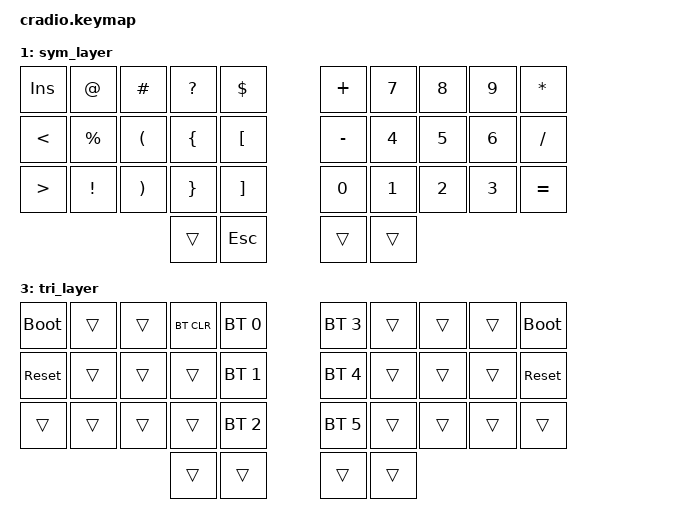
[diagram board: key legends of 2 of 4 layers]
// Copyright (c) 2022 The ZMK Contributors
// SPDX-License-Identifier: MIT

#include <behaviors.dtsi>
#include <dt-bindings/zmk/keys.h>
#include <dt-bindings/zmk/bt.h>

// Home row mods macro
#define HRML(k1,k2,k3,k4) &ht LCTRL k1  &ht LGUI k2  &ht LALT k3  &ht LCTRL k4
#define HRMR(k1,k2,k3,k4) &ht RCTRL k1  &ht RALT k2  &ht RGUI k3  &ht RCTRL k4

#define BASE    0
#define SYM     1
#define NAV     2

/ {
    behaviors {
        ht: hold_tap {
            compatible = "zmk,behavior-hold-tap";
            #binding-cells = <2>;
            flavor = "tap-preferred";
            tapping-term-ms = <220>;
            quick-tap-ms = <150>;
            require-prior-idle-ms = <100>;
            bindings = <&kp>, <&kp>;
        };
    };

    conditional_layers {
        compatible = "zmk,conditional-layers";
        tri_layer {
            if-layers = <1 2>;
            then-layer = <3>;
        };
    };

    keymap {
        compatible = "zmk,keymap";
        default_layer {
            bindings = <
        //╭──────────┬──────────┬──────────┬──────────┬──────────╮   ╭──────────┬──────────┬──────────┬──────────┬──────────╮
        //│  Q       │  W       │  E       │  R       │  T       │   │  Y       │  U       │  I       │  O       │  P       │
            &kp Q      &kp W      &kp E      &kp R      &kp T          &kp Y      &kp U      &kp I      &kp O      &kp P
        //├──────────┼──────────┼──────────┼──────────┼──────────┤   ├──────────┼──────────┼──────────┼──────────┼──────────┤
        //│  A       │  S       │  D       │  F       │  G       │   │  H       │  J       │  K       │  L       │          │
            HRML(A,     S,         D,         F)        &kp G          &kp H      HRMR(J,     K,         L,        BSPC)
        //├──────────┼──────────┼──────────┼──────────┼──────────┤   ├──────────┼──────────┼──────────┼──────────┼──────────┤
        //│  Z       │  X       │  C       │  V       │  B       │   │  N       │  M       │ , <      │ . >      │          │
            &kp Z      &kp X      &kp C      &kp V      &kp B          &kp N      &kp M      &kp COMMA  &kp DOT    &kp ENTER
        //╰──────────┴──────────┴──────────┼──────────┼──────────┤   ├──────────┼──────────┼──────────┴──────────┴──────────╯
                                           &lt NAV TAB &kp LSHFT     &kp BSPC   &lt SYM SPACE
        //                                 ╰──────────┴──────────╯   ╰──────────┴──────────╯
            >;
        };

        sym_layer {
            bindings = <
        //╭──────────┬──────────┬──────────┬──────────┬──────────╮   ╭──────────┬──────────┬──────────┬──────────┬──────────╮
        //│  !       │  @       │  #       │  ?       │  $       │   │  +       │  7       │  8       │  9       │  *       │
            &kp INS    &kp AT     &kp HASH   &kp QMARK  &kp DLLR       &kp PLUS   &kp N7     &kp N8     &kp N9     &kp ASTRK 
        //├──────────┼──────────┼──────────┼──────────┼──────────┤   ├──────────┼──────────┼──────────┼──────────┼──────────┤
        //│  <       │  %       │  (       │  {       │  [       │   │  -       │  4       │  5       │  6       │  /       │
            &kp LT    &kp PRCNT   &kp LPAR   &kp LBRC   &kp LBKT       &kp MINUS  &kp N4     &kp N5     &kp N6     &kp FSLH  
        //├──────────┼──────────┼──────────┼──────────┼──────────┤   ├──────────┼──────────┼──────────┼──────────┼──────────┤
        //│  >       │  !       │  )       │  }       │  ]       │   │  0       │  1       │  2       │  3       │  =       │
            &kp GT     &kp EXCL   &kp RPAR   &kp RBRC   &kp RBKT       &kp N0     &kp N1     &kp N2     &kp N3     &kp EQUAL 
        //╰──────────┴──────────┴──────────┼──────────┼──────────┤   ├──────────┼──────────┼──────────┴──────────┴──────────╯
                                             &trans     &kp ESC        &trans     &trans
        //                                 ╰──────────┴──────────╯   ╰──────────┴──────────╯
            >;
        };

        nav_layer {
            bindings = <
        //╭──────────┬──────────┬──────────┬──────────┬──────────╮   ╭──────────┬──────────┬──────────┬──────────┬──────────╮
        //│          │          │  ;       │  ^       │          │   │  PAGE UP │  HOME    │  UP      │  END     │  DELETE  │
            &trans     &trans     &kp SEMI   &kp CARET  &trans         &kp PG_UP  &kp HOME   &kp UARW   &kp END    &kp DEL   
        //├──────────┼──────────┼──────────┼──────────┼──────────┤   ├──────────┼──────────┼──────────┼──────────┼──────────┤
        //│  `       │  ~       │  _       │  &       │  │       │   │  PAGE DN │  LEFT    │  DOWN    │  RIGHT   │  BSPC    │
           HRML(GRAVE, TILDE,     UNDER,     AMPS)      &kp PIPE       &kp PG_DN  &kp LARW   &kp DARW   &kp RARW   &trans
        //├──────────┼──────────┼──────────┼──────────┼──────────┤   ├──────────┼──────────┼──────────┼──────────┼──────────┤
        //│ INSERT   │ CAPS     │  :       │  \       │          │   │  &       │  _       │  +       │  │       │          │
            &kp INS    &caps_word &kp COLON  &kp BSLH   &trans         &kp AMPS   &kp UNDER  &kp PLUS   &kp PIPE   &trans
        //╰──────────┴──────────┴──────────┼──────────┼──────────┤   ├──────────┼──────────┼──────────┴──────────┴──────────╯
                                             &trans     &trans         &trans     &trans
        //                                 ╰──────────┴──────────╯   ╰──────────┴──────────╯
            >;
        };

        tri_layer {
            bindings = <
        //╭──────────┬──────────┬──────────┬──────────┬──────────╮   ╭──────────┬──────────┬──────────┬──────────┬──────────╮
        //│BOOTLOADER│          │          │ CLEAR BT │PROFILE 0 │   │PROFILE 3 │          │          │          │BOOTLOADER│
          &bootloader  &trans     &trans    &bt BT_CLR &bt BT_SEL 0  &bt BT_SEL 3 &trans     &trans     &trans    &bootloader
        //├──────────┼──────────┼──────────┼──────────┼──────────┤   ├──────────┼──────────┼──────────┼──────────┼──────────┤
        //│  RESET   │          │          │          │PROFILE 1 │   │PROFILE 4 │          │          │          │  RESET   │
          &sys_reset   &trans     &trans     &trans    &bt BT_SEL 1  &bt BT_SEL 4 &trans     &trans     &trans    &sys_reset 
        //├──────────┼──────────┼──────────┼──────────┼──────────┤   ├──────────┼──────────┼──────────┼──────────┼──────────┤
        //│          │          │          │          │PROFILE 2 │   │PROFILE 5 │          │          │          │          │
            &trans     &trans     &trans     &trans    &bt BT_SEL 2  &bt BT_SEL 5 &trans     &trans     &trans     &trans
        //╰──────────┴──────────┴──────────┼──────────┼──────────┤   ├──────────┼──────────┼──────────┴──────────┴──────────╯
                                             &trans     &trans         &trans     &trans
        //                                 ╰──────────┴──────────╯   ╰──────────┴──────────╯
            >;
        };
    };
};
